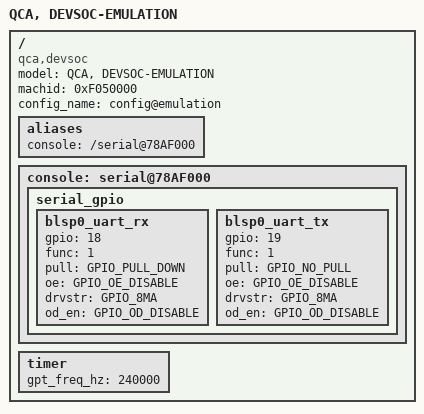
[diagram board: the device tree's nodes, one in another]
/*
 * Copyright (c) 2016-2019, The Linux Foundation. All rights reserved.
 *
 * Copyright (c) 2022 Qualcomm Innovation Center, Inc. All rights reserved.
 *
 * This program is free software; you can redistribute it and/or modify
 * it under the terms of the GNU General Public License version 2 and
 * only version 2 as published by the Free Software Foundation.
 *
 * This program is distributed in the hope that it will be useful,
 * but WITHOUT ANY WARRANTY; without even the implied warranty of
 * MERCHANTABILITY or FITNESS FOR A PARTICULAR PURPOSE.  See the
 * GNU General Public License for more details.
 */

/dts-v1/;
#include "devsoc-soc.dtsi"
/ {
	model ="QCA, DEVSOC-EMULATION";
	compatible = "qca,devsoc", "qca,devsoc-emulation";
	machid = <0xF050000>;
	config_name = "config@emulation";

	aliases {
		console = "/serial@78AF000";
	};

	console: serial@78AF000 {
		status = "ok";
		serial_gpio {
			blsp0_uart_rx {
				gpio = <18>;
				func = <1>;
				pull = <GPIO_PULL_DOWN>;
				oe = <GPIO_OE_DISABLE>;
				drvstr = <GPIO_8MA>;
				od_en = <GPIO_OD_DISABLE>;
			};
			blsp0_uart_tx {
				gpio = <19>;
				func = <1>;
				pull = <GPIO_NO_PULL>;
				oe = <GPIO_OE_DISABLE>;
				drvstr = <GPIO_8MA>;
				od_en = <GPIO_OD_DISABLE>;
			};
		};
	};

	timer {
		gpt_freq_hz = <240000>;
	};
};
